# cslr_icachec5510_001 register map
Vendor: Texas Instruments
Peripheral module from a debugger description file.
Registers are 16-bit, read-write, reset 0x0 unless marked. A register's access mark holds for its fields unless they carry their own. Offsets are as the file gives them; lines under a group give offsets from that group; [hi:lo] are bit positions; {n}, {i} and the like mark numbered series; 'fields as' and 'values as' point back to an identical list; <NAME> marks a mode.

## ICACHE — Instruction Cache
0x00 ICGC reset not defined — I-Cache Global Control Register
  [15:0] RMODE — RAM-set mode bits
    0xCBFF=CBFFh (No RAM sets); 0xCE1F=CE1Fh (1 RAM set. Only RAM set 1 is available.); 0xCFFF=CFFFh (2 RAM sets. RAM set 1 and RAM set 2 are available.)
0x03 ICWC access per field (reset mask 0xFFE0) — I-Cache Way Control Register
  [4:0] WINIT rw — Way initialization bits.
0x04 ICST ro — I-Cache Status Register
  [2] IEN — I-Cache-enabled bit.
    0=The I-Cache is disabled; 1=The I-Cache is enabled
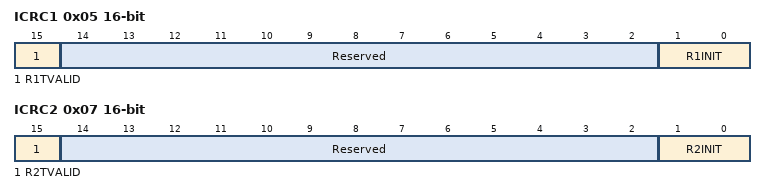
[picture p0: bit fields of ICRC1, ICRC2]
0x05 ICRC1 access per field (reset mask 0x8000) — I-Cache RAM Set Control Register 1
  [15] R1TVALID ro — RAM set 1 tag-valid bit.
    0=The fill is not started or is not complete; 1=The fill is complete
  [14:2] Reserved ro — These read-only bits are not used.
  [1:0] R1INIT rw
    3=11b (RAM set 1 initialization bits.)
0x06 ICRTAG1 — I-Cache RAM Set 1 Tag Register
  [15:0] R1TAG — RAM set 1 tag bits.
0x07 ICRC2 access per field (reset mask 0x8000) — I-Cache RAM Set Control Register 2
  [15] R2TVALID ro — RAM set 2 tag-valid bit.
    values as ICRC1.R1TVALID
  [14:2] Reserved ro — These read-only bits are not used.
  [1:0] R2INIT rw
    3=11b (RAM set 2 initialization bits.)
0x08 ICRTAG2 — I-Cache RAM Set 2 Tag Register
  [15:0] R2TAG — RAM set 2 tag bits.
